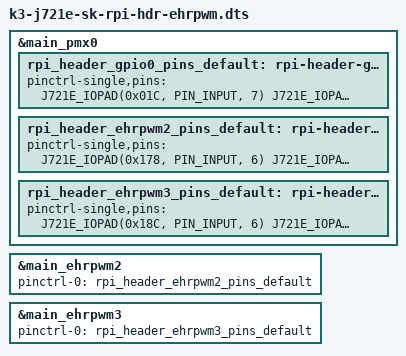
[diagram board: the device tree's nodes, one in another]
// SPDX-License-Identifier: GPL-2.0
/**
 * DT Overlay for enabling EHRPWMs on RPi expansion header on J721E SK board.
 *
 * Copyright (C) 2022 Texas Instruments Incorporated - https://www.ti.com/
 */

/dts-v1/;
/plugin/;

#include <dt-bindings/gpio/gpio.h>
#include <dt-bindings/interrupt-controller/irq.h>
#include <dt-bindings/pinctrl/k3.h>

&main_pmx0 {
	rpi_header_gpio0_pins_default: rpi-header-gpio0-pins-default {
		pinctrl-single,pins = <
			J721E_IOPAD(0x01C, PIN_INPUT, 7) /* (AD22) PRG1_PRU0_GPO6.GPIO0_7 */
			J721E_IOPAD(0x120, PIN_INPUT, 7) /* (AD28) PRG0_PRU1_GPO8.GPIO0_71 */
			J721E_IOPAD(0x14C, PIN_INPUT, 7) /* (AD29) PRG0_PRU1_GPO19.GPIO0_82 */
			J721E_IOPAD(0x02C, PIN_INPUT, 7) /* (AD21) PRG1_PRU0_GPO10.GPIO0_11 */
			J721E_IOPAD(0x198, PIN_INPUT, 7) /* (V25) RGMII6_TD1.GPIO0_101 */
			J721E_IOPAD(0x1B0, PIN_INPUT, 7) /* (W24) RGMII6_RD1.GPIO0_107 */
			J721E_IOPAD(0x1A0, PIN_INPUT, 7) /* (W29) RGMII6_TXC.GPIO0_103 */
			J721E_IOPAD(0x008, PIN_INPUT, 7) /* (AG22) PRG1_PRU0_GPO1.GPIO0_2 */
			J721E_IOPAD(0x1D0, PIN_INPUT, 7) /* (AA3) SPI0_D1.GPIO0_115 */
			J721E_IOPAD(0x11C, PIN_INPUT, 7) /* (AA24) PRG0_PRU1_GPO7.GPIO0_70 */
			J721E_IOPAD(0x148, PIN_INPUT, 7) /* (AA26) PRG0_PRU1_GPO18.GPIO0_81 */
			J721E_IOPAD(0x004, PIN_INPUT, 7) /* (AC23) PRG1_PRU0_GPO0.GPIO0_1 */
			J721E_IOPAD(0x014, PIN_INPUT, 7) /* (AH23) PRG1_PRU0_GPO4.GPIO0_5 */
			J721E_IOPAD(0x020, PIN_INPUT, 7) /* (AE20) PRG1_PRU0_GPO7.GPIO0_8 */
			J721E_IOPAD(0x19C, PIN_INPUT, 7) /* (W27) RGMII6_TD0.GPIO0_102 */
			J721E_IOPAD(0x1B4, PIN_INPUT, 7) /* (W25) RGMII6_RD0.GPIO0_108 */
			J721E_IOPAD(0x188, PIN_INPUT, 7) /* (Y28) RGMII6_TX_CTL.GPIO0_97 */
			J721E_IOPAD(0x00C, PIN_INPUT, 7) /* (AF22) PRG1_PRU0_GPO2.GPIO0_3 */
			J721E_IOPAD(0x010, PIN_INPUT, 7) /* (AJ23) PRG1_PRU0_GPO3.GPIO0_4 */
		>;
	};

	rpi_header_ehrpwm2_pins_default: rpi-header-ehrpwm2-pins-default {
		pinctrl-single,pins = <
			J721E_IOPAD(0x178, PIN_INPUT, 6) /* (U27) RGMII5_RD3.EHRPWM2_A */
			J721E_IOPAD(0x17C, PIN_INPUT, 6) /* (U24) RGMII5_RD2.EHRPWM2_B */
		>;
	};

	rpi_header_ehrpwm3_pins_default: rpi-header-ehrpwm3-pins-default {
		pinctrl-single,pins = <
			J721E_IOPAD(0x18C, PIN_INPUT, 6) /* (V23) RGMII6_RX_CTL.EHRPWM3_A */
			J721E_IOPAD(0x190, PIN_INPUT, 6) /* (W23) RGMII6_TD3.EHRPWM3_B */
		>;
	};
};

&main_ehrpwm2 {
	pinctrl-names = "default";
	pinctrl-0 = <&rpi_header_ehrpwm2_pins_default>;
	status = "okay";
};

&main_ehrpwm3 {
	pinctrl-names = "default";
	pinctrl-0 = <&rpi_header_ehrpwm3_pins_default>;
	status = "okay";
};
